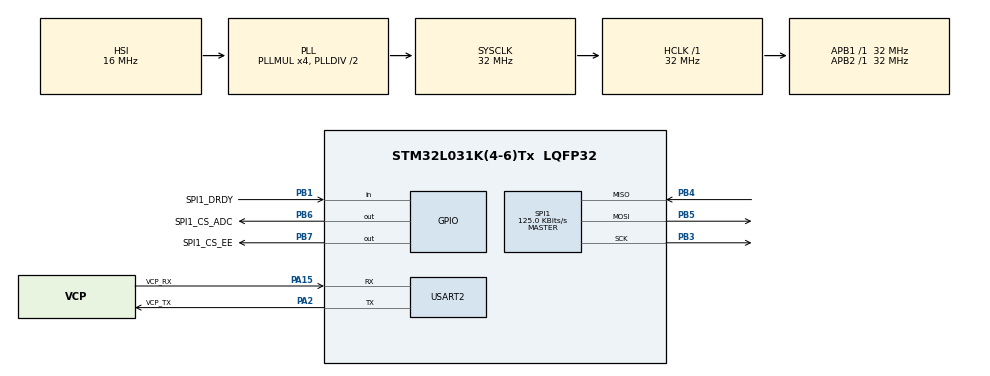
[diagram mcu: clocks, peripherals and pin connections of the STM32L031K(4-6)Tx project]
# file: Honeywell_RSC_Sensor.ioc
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Mcu.Family=STM32L0
Mcu.Name=STM32L031K(4-6)Tx
Mcu.Package=LQFP32
PA13.GPIO_Label=TMS
PA13.Mode=Serial_Wire
PA13.Signal=SYS_SWDIO
PA14.GPIO_Label=TCK
PA14.Mode=Serial_Wire
PA14.Signal=SYS_SWCLK
PA15.GPIO_Label=VCP_RX
PA15.Mode=Asynchronous
PA15.Signal=USART2_RX
PA2.GPIO_Label=VCP_TX
PA2.Mode=Asynchronous
PA2.Signal=USART2_TX
PB1.GPIO_Label=SPI1_DRDY
PB1.Signal=GPIO_Input
PB3.Mode=Full_Duplex_Master
PB3.Signal=SPI1_SCK
PB4.Mode=Full_Duplex_Master
PB4.Signal=SPI1_MISO
PB5.Mode=Full_Duplex_Master
PB5.Signal=SPI1_MOSI
PB6.GPIO_Label=SPI1_CS_ADC
PB6.Signal=GPIO_Output
PB7.GPIO_Label=SPI1_CS_EE
PB7.Signal=GPIO_Output
ProjectManager.HeapSize=0x200
ProjectManager.StackSize=0x400
ProjectManager.TargetToolchain=STM32CubeIDE
RCC.AHBFreq_Value=32000000
RCC.APB1Freq_Value=32000000
RCC.APB1TimFreq_Value=32000000
RCC.APB2Freq_Value=32000000
RCC.APB2TimFreq_Value=32000000
RCC.HCLKFreq_Value=32000000
RCC.HSE_VALUE=8000000
RCC.HSI16_VALUE=16000000
RCC.HSI48_VALUE=48000000
RCC.HSI_VALUE=16000000
RCC.LSE_VALUE=32768
RCC.MSI_VALUE=2097000
RCC.PLLMUL=RCC_PLLMUL_4
RCC.SYSCLKFreq_VALUE=32000000
RCC.SYSCLKSource=RCC_SYSCLKSOURCE_PLLCLK
RCC.VCOOutputFreq_Value=64000000
SPI1.BaudRatePrescaler=SPI_BAUDRATEPRESCALER_256
SPI1.CLKPhase=SPI_PHASE_1EDGE
SPI1.CLKPolarity=SPI_POLARITY_LOW
SPI1.CalculateBaudRate=125.0 KBits/s
SPI1.Direction=SPI_DIRECTION_2LINES
SPI1.FirstBit=SPI_FIRSTBIT_MSB
SPI1.Mode=SPI_MODE_MASTER
SPI1.VirtualType=VM_MASTER
USART2.VirtualMode-Asynchronous=VM_ASYNC
board=NUCLEO-L031K6

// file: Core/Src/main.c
/* USER CODE BEGIN Header */
/**
  ******************************************************************************
  * @file           : main.c
  * @brief          : Main program body
  ******************************************************************************
  * @attention
  *
  * <h2><center>&copy; Copyright (c) 2020 STMicroelectronics.
  * All rights reserved.</center></h2>
  *
  * This software component is licensed by ST under BSD 3-Clause license,
  * the "License"; You may not use this file except in compliance with the
  * License. You may obtain a copy of the License at:
  *                        opensource.org/licenses/BSD-3-Clause
  *
  ******************************************************************************
  */
/* USER CODE END Header */

#include "main.h"

SPI_HandleTypeDef hspi1;

UART_HandleTypeDef huart2;

void SystemClock_Config(void);
static void MX_GPIO_Init(void);
static void MX_USART2_UART_Init(void);
static void MX_SPI1_Init(void);

int main(void)
{

  /* MCU Configuration--------------------------------------------------------*/

  /* Reset of all peripherals, Initializes the Flash interface and the Systick. */
  HAL_Init();

  /* Configure the system clock */
  SystemClock_Config();

  /* Initialize all configured peripherals */
  MX_GPIO_Init();
  MX_USART2_UART_Init();
  MX_SPI1_Init();

  /* Infinite loop */
  /* USER CODE BEGIN WHILE */
	HAL_SPI_DeInit(&hspi1);
	DrvSPIInit();
	while (1)
	{
	float asd = get_temperature();
	float presasd = get_pressure();
	HAL_Delay(500);
    /* USER CODE END WHILE */

  }
}

void SystemClock_Config(void)
{
  RCC_OscInitTypeDef RCC_OscInitStruct = {0};
  RCC_ClkInitTypeDef RCC_ClkInitStruct = {0};
  RCC_PeriphCLKInitTypeDef PeriphClkInit = {0};

  /** Configure the main internal regulator output voltage
  */
  __HAL_PWR_VOLTAGESCALING_CONFIG(PWR_REGULATOR_VOLTAGE_SCALE1);
  /** Initializes the CPU, AHB and APB busses clocks
  */
  RCC_OscInitStruct.OscillatorType = RCC_OSCILLATORTYPE_HSI;
  RCC_OscInitStruct.HSIState = RCC_HSI_ON;
  RCC_OscInitStruct.HSICalibrationValue = RCC_HSICALIBRATION_DEFAULT;
  RCC_OscInitStruct.PLL.PLLState = RCC_PLL_ON;
  RCC_OscInitStruct.PLL.PLLSource = RCC_PLLSOURCE_HSI;
  RCC_OscInitStruct.PLL.PLLMUL = RCC_PLLMUL_4;
  RCC_OscInitStruct.PLL.PLLDIV = RCC_PLLDIV_2;
  if (HAL_RCC_OscConfig(&RCC_OscInitStruct) != HAL_OK)
  {
    Error_Handler();
  }
  /** Initializes the CPU, AHB and APB busses clocks
  */
  RCC_ClkInitStruct.ClockType = RCC_CLOCKTYPE_HCLK|RCC_CLOCKTYPE_SYSCLK
                              |RCC_CLOCKTYPE_PCLK1|RCC_CLOCKTYPE_PCLK2;
  RCC_ClkInitStruct.SYSCLKSource = RCC_SYSCLKSOURCE_PLLCLK;
  RCC_ClkInitStruct.AHBCLKDivider = RCC_SYSCLK_DIV1;
  RCC_ClkInitStruct.APB1CLKDivider = RCC_HCLK_DIV1;
  RCC_ClkInitStruct.APB2CLKDivider = RCC_HCLK_DIV1;

  if (HAL_RCC_ClockConfig(&RCC_ClkInitStruct, FLASH_LATENCY_1) != HAL_OK)
  {
    Error_Handler();
  }
  PeriphClkInit.PeriphClockSelection = RCC_PERIPHCLK_USART2;
  PeriphClkInit.Usart2ClockSelection = RCC_USART2CLKSOURCE_PCLK1;
  if (HAL_RCCEx_PeriphCLKConfig(&PeriphClkInit) != HAL_OK)
  {
    Error_Handler();
  }
}

static void MX_SPI1_Init(void)
{

  /* SPI1 parameter configuration*/
  hspi1.Instance = SPI1;
  hspi1.Init.Mode = SPI_MODE_MASTER;
  hspi1.Init.Direction = SPI_DIRECTION_2LINES;
  hspi1.Init.DataSize = SPI_DATASIZE_8BIT;
  hspi1.Init.CLKPolarity = SPI_POLARITY_LOW;
  hspi1.Init.CLKPhase = SPI_PHASE_1EDGE;
  hspi1.Init.NSS = SPI_NSS_SOFT;
  hspi1.Init.BaudRatePrescaler = SPI_BAUDRATEPRESCALER_256;
  hspi1.Init.FirstBit = SPI_FIRSTBIT_MSB;
  hspi1.Init.TIMode = SPI_TIMODE_DISABLE;
  hspi1.Init.CRCCalculation = SPI_CRCCALCULATION_DISABLE;
  hspi1.Init.CRCPolynomial = 7;
  if (HAL_SPI_Init(&hspi1) != HAL_OK)
  {
    Error_Handler();
  }

}

static void MX_USART2_UART_Init(void)
{

  huart2.Instance = USART2;
  huart2.Init.BaudRate = 115200;
  huart2.Init.WordLength = UART_WORDLENGTH_8B;
  huart2.Init.StopBits = UART_STOPBITS_1;
  huart2.Init.Parity = UART_PARITY_NONE;
  huart2.Init.Mode = UART_MODE_TX_RX;
  huart2.Init.HwFlowCtl = UART_HWCONTROL_NONE;
  huart2.Init.OverSampling = UART_OVERSAMPLING_16;
  huart2.Init.OneBitSampling = UART_ONE_BIT_SAMPLE_DISABLE;
  huart2.AdvancedInit.AdvFeatureInit = UART_ADVFEATURE_NO_INIT;
  if (HAL_UART_Init(&huart2) != HAL_OK)
  {
    Error_Handler();
  }

}

static void MX_GPIO_Init(void)
{
  GPIO_InitTypeDef GPIO_InitStruct = {0};

  /* GPIO Ports Clock Enable */
  __HAL_RCC_GPIOA_CLK_ENABLE();
  __HAL_RCC_GPIOB_CLK_ENABLE();

  /*Configure GPIO pin Output Level */
  HAL_GPIO_WritePin(GPIOB, SPI1_CS_ADC_Pin|SPI1_CS_EE_Pin, GPIO_PIN_RESET);

  /*Configure GPIO pin : SPI1_DRDY_Pin */
  GPIO_InitStruct.Pin = SPI1_DRDY_Pin;
  GPIO_InitStruct.Mode = GPIO_MODE_INPUT;
  GPIO_InitStruct.Pull = GPIO_NOPULL;
  HAL_GPIO_Init(SPI1_DRDY_GPIO_Port, &GPIO_InitStruct);

  /*Configure GPIO pins : SPI1_CS_ADC_Pin SPI1_CS_EE_Pin */
  GPIO_InitStruct.Pin = SPI1_CS_ADC_Pin|SPI1_CS_EE_Pin;
  GPIO_InitStruct.Mode = GPIO_MODE_OUTPUT_PP;
  GPIO_InitStruct.Pull = GPIO_NOPULL;
  GPIO_InitStruct.Speed = GPIO_SPEED_FREQ_LOW;
  HAL_GPIO_Init(GPIOB, &GPIO_InitStruct);

}

void Error_Handler(void)
{
}

/************************ (C) COPYRIGHT STMicroelectronics *****END OF FILE****/
